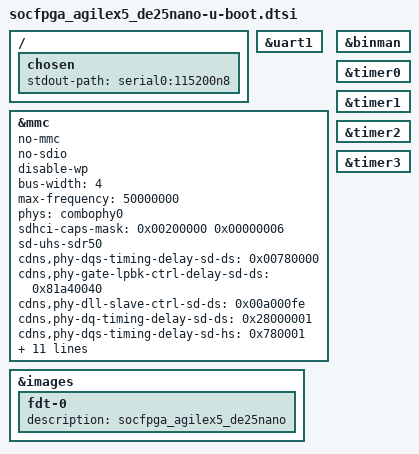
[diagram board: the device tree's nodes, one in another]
// SPDX-License-Identifier: GPL-2.0+
/*
 * U-Boot additions for the Terasic DE25-Nano.
 *
 * U-Boot's build automatically #includes <board>-u-boot.dtsi next to
 * <board>.dts (scripts/Makefile.lib, u_boot_dtsi_options), which is why this
 * file has no entry anywhere in the config: it is found by NAME. Rename the
 * .dts and this file must be renamed in the same commit or the board silently
 * loses everything below -- including the FIT description, which is the entire
 * output of this build.
 *
 * Modelled on mainline v2026.07's arch/arm/dts/socfpga_agilex5_socdk-u-boot.dtsi.
 */

/*
 * LOAD-BEARING, AND NOT OPTIONAL: this pulls in socfpga_agilex5-u-boot.dtsi,
 * which in turn #includes socfpga_soc64_fit-u-boot.dtsi -- the binman
 * description that IS u-boot.itb. Without this line the build produces a
 * working U-Boot binary and no FIT at all.
 */
#include "socfpga_agilex5-u-boot.dtsi"

/*
 * Reset manager: NO altr,modrst-offset override. Effective value is <0x24>
 * from socfpga_agilex5-u-boot.dtsi — and that is EXACTLY what Terasic's
 * de25-nano-v2025.01 ships in their socfpga_agilex5-u-boot.dtsi (verified).
 * On this board any REAL write into the rstmgr bank registers kills SPTIMER0:
 * measured on hardware — offset 0x14 sends the timer's own reset-deassert
 * (id 38, bank 1) to 0x10d11018, and one RMW write of 0 there zeroes the
 * dw-apb-timer registers (frozen get_timer, instant udelay, never-expiring
 * polls, "dead" autoboot countdown). Offset 0x10 + ComboPHY killed it too
 * (the ComboPHY reset cycle writes bank 0 for real). Only 0x24 — writes that
 * miss the register block entirely — leaves the timer alive, which is how the
 * factory SPL/U-Boot coexist with it. Corollary: the ComboPHY reset cycle is
 * a no-op for us; the SD link works off the ComboPHY register programming
 * alone (factory-proven). Do NOT reintroduce an override here.
 */

/ {
	chosen {
		/*
		 * serial0 is aliased to uart1 in the .dts. 115200 8N1 is what the
		 * board's USB-UART bridge and every reference tree use.
		 *
		 * NOTE what is NOT here: mainline's socdk carries
		 *   u-boot,spl-boot-order = &mmc,&flash0,&nand,"/memory";
		 * That property is read by board_boot_order() in SPL. OUR SPL
		 * NEVER RUNS -- the factory SPL in QSPI does, from its own DTB,
		 * whose boot order is already known and fixed:
		 *   "/soc/mmc0@10808000", "/soc/spi@108d2000/flash@0",
		 *   "/soc/nand@10b80000", "/memory"
		 * (docs/de25-boot-chain.md section 2). Restating it here would
		 * describe a decision we do not get to make, and referencing
		 * &flash0 would not even compile: this board file deliberately
		 * declares no QSPI flash node.
		 */
		stdout-path = "serial0:115200n8";
	};
};

&uart1 {
	/*
	 * socfpga_agilex5-u-boot.dtsi marks &uart0 bootph-all because socdk's
	 * console is uart0. Ours is uart1, and without this marking the node is
	 * not bound before relocation, so every printf between board_init_f and
	 * relocation is lost -- which is precisely the window where a bring-up
	 * failure would be diagnosed.
	 */
	bootph-all;
};

&mmc {
	/* No UHS or regulator; PHY values are socdk's. Default speed, 25 MHz.
	 * The ComboPHY analog frontend is attached via phys/phy-names below;
	 * its driver does the PER0MODRST reset cycle by direct register write
	 * (see the build-tree phy-cadence-combophy.c) because the board-wide
	 * modrst offset must stay 0x24 to keep SPTIMER0 alive. The cdns,phy-*
	 * values feed mainline sdhci_cdns6_phy_init (HRS04/HRS05 + HRS09/10/
	 * 16/07) and are REQUIRED for card detection on this stack (-110
	 * without them). Rationale: docs/de25-uboot.md section 5.1, bring-up
	 * sessions 2-3. */
	status = "okay";
	no-mmc;
	no-sdio;
	disable-wp;
	bus-width = <4>;
	max-frequency = <25000000>;

	phys = <&combophy0>;
	phy-names = "combo-phy";

	/* SDR50 LIFT: the factory Terasic stack runs SDR50 on this board with
	 * NO vmmc/vqmmc regulators (their u-boot has none and boots 10/10), so
	 * the 1.8V switch is handled by the hardware/SDM path. Mask keeps SDR50
	 * (CAPS1 bit 0) and hides SDR104 (bit 1) + DDR50 (bit 2). If this
	 * regresses, revert to golden: caps-mask <0x00200000 0x00000007>,
	 * no sd-uhs-sdr50, max-frequency 25000000. */
	sdhci-caps-mask = <0x00200000 0x00000006>;
	sd-uhs-sdr50;
	max-frequency = <50000000>;

	/* SD card default speed (DS) and UHS-I SDR12 mode timing configuration */
	cdns,phy-dqs-timing-delay-sd-ds = <0x00780000>;
	cdns,phy-gate-lpbk-ctrl-delay-sd-ds = <0x81a40040>;
	cdns,phy-dll-slave-ctrl-sd-ds = <0x00a000fe>;
	cdns,phy-dq-timing-delay-sd-ds = <0x28000001>;

	/* SD high speed / UHS-I SDR25 timing (used when high speed is on) */
	cdns,phy-dqs-timing-delay-sd-hs = <0x780001>;
	cdns,phy-gate-lpbk-ctrl-delay-sd-hs = <0x81a40040>;
	cdns,phy-dq-timing-delay-sd-hs = <0x10000001>;
	cdns,ctrl-hrs16-slave-ctrl-sd-hs = <0x101>;
	cdns,ctrl-hrs07-timing-delay-sd-hs = <0xA0001>;

	/* UHS SDR50 uses the mainline emmc_sdr table
	 * (sdhci_cdns6_phy_adj case UHS_SDR50/MMC_HS_52). Its built-in defaults
	 * (hrs16=0, hrs07=0x80000) break 1.8V/4-bit reads on this board, while
	 * the sd-hs set above works (SDR25 1-bit proved it). Mirror the sd-hs
	 * values onto the emmc_sdr slots so SDR50 applies the same timings. */
	cdns,phy-dqs-timing-delay-emmc-sdr = <0x780001>;
	cdns,phy-gate-lpbk-ctrl-delay-emmc-sdr = <0x81a40040>;
	cdns,phy-dq-timing-delay-emmc-sdr = <0x10000001>;
	cdns,ctrl-hrs16-slave-ctrl-emmc-sdr = <0x101>;
	cdns,ctrl-hrs07-timing-delay-emmc-sdr = <0xA0001>;

	bootph-all;
};

/*
 * Name the FIT's fdt-0 after this board.
 *
 * socfpga_soc64_fit-u-boot.dtsi hardcodes description = "socfpga_socdk" for
 * every SoC64 board. It is a description string with no functional effect --
 * board_fit_config_name_match() compares the CONFIGURATION node's description,
 * not the image's -- but "socfpga_socdk" in a DE25 artifact is exactly the kind
 * of label that gets believed later. docs/de25-implementation-path.md section
 * 6.1 asks for it to be renamed per board.
 */
&images {
	fdt-0 {
		description = "socfpga_agilex5_de25nano";
	};
};

/*
 * Drop the kernel.itb image from the binman description.
 *
 * TWO independent reasons, and either alone would be sufficient:
 *
 * 1. WE DO NOT SHIP kernel.itb. This board boots via extlinux: U-Boot reads
 *    extlinux/extlinux.conf off the FAT partition and loads Image + dtb as
 *    plain files. A second, unused, unsigned FIT carrying a copy of the kernel
 *    is a redundant artifact whose staleness nobody would notice.
 *
 * 2. WITHOUT THIS, THE BUILD FAILS. binman is invoked with --allow-missing
 *    --fake-ext-blobs but WITHOUT --ignore-missing (U-Boot's Makefile only
 *    adds the latter when BINMAN_ALLOW_MISSING is set), and it returns 103 --
 *    "Some images are invalid" -- if any image is missing an external blob.
 *    The kernel image's blob-ext entries are "Image" and "linux.dtb". Buildroot
 *    passes BINMAN_INDIRS=$(BINARIES_DIR), so binman does find images/Image --
 *    but nothing in this project ever produces a file called linux.dtb (ours
 *    is socfpga_agilex5_de25nano.dtb), so kernel.itb can never be complete.
 *
 * The alternative fixes were setting BINMAN_ALLOW_MISSING=1 -- which would
 * ALSO silence a genuinely missing bl31.bin, the one blob whose absence must
 * never be silent -- or patching U-Boot. Deleting the node we do not want is
 * smaller than both and needs no patch. The reference DE25 tree does the same
 * thing in the same place.
 */
&binman {
	/delete-node/ kernel;
};

&timer0 {
   bootph-all;
};

&timer1 {
   bootph-all;
};

&timer2 {
   bootph-all;
};

&timer3 {
   bootph-all;
};

